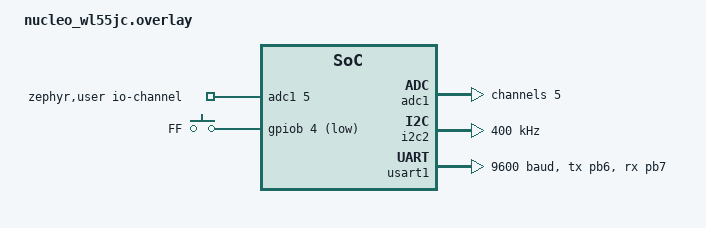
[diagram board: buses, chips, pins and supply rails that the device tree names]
/*
 * SPDX-License-Identifier: Apache-2.0
 *
 * Copyright (c) 2022 QRTECH
 */

/ {
	zephyr,user {
		io-channels = <&adc1 5>;
	};

	gpio_keys {
		compatible = "gpio-keys";

		accel_interrup: adc_in1_pb4 {
			label = "FF";
			gpios = <&gpiob 4 (GPIO_ACTIVE_LOW | GPIO_PULL_UP)>;
			zephyr,code = <INPUT_KEY_3>;
		};
	};

	aliases {
		ff0 = &accel_interrup;
	};

};

&adc1 {
	#address-cells = <1>;
	#size-cells = <0>;

	channel@5 {
		reg = <5>;
		zephyr,gain = "ADC_GAIN_1";
		zephyr,reference = "ADC_REF_INTERNAL";
		zephyr,acquisition-time = <ADC_ACQ_TIME_DEFAULT>;
		zephyr,resolution = <12>;
	};
};

&i2c2 {
    status = "okay";
    clock-frequency = <I2C_BITRATE_FAST>; // 400kHz
};

&usart1 {
	dmas = <&dmamux1 11 18 (STM32_DMA_PERIPH_TX | STM32_DMA_PRIORITY_HIGH)
		&dmamux1 1 17 (STM32_DMA_PERIPH_RX | STM32_DMA_PRIORITY_HIGH)>;
	dma-names = "tx", "rx";
	pinctrl-0 = <&usart1_tx_pb6 &usart1_rx_pb7>;
	pinctrl-names = "default";
	current-speed = <9600>;
	status = "okay";
};

&dma1 {
	status = "okay";
};

&dma2 {
	status = "okay";
};

&dmamux1 {
	status = "okay";
};

&gpiob {
    status = "okay";
};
